# STM32F412CEU6 register map
File version: 1.0
Registers are 32-bit, access not given, reset 0x0 unless marked. A register's access mark holds for its fields unless they carry their own. Offsets are from the block's base; [hi:lo] are bit positions; {n}, {i} and the like mark numbered series; 'fields as' and 'values as' point back to an identical list.

## GPIOA
Base 0x40020000
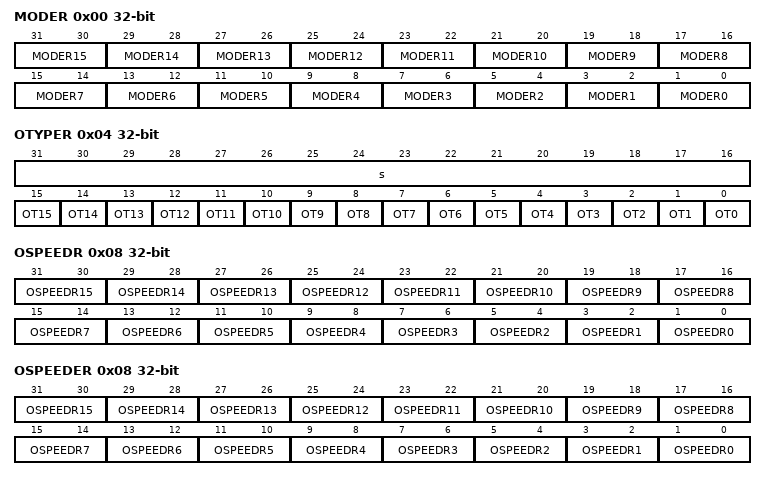
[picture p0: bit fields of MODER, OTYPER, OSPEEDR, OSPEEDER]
0x00 MODER
  [2n+1:2n] MODER{n} (n=0..15)
0x04 OTYPER
  [31:16] s, [n] OT{n} (n=0..15)
0x08 OSPEEDR
  [2n+1:2n] OSPEEDR{n} (n=0..15)
0x08 OSPEEDER
  [2n+1:2n] OSPEEDR{n} (n=0..15)
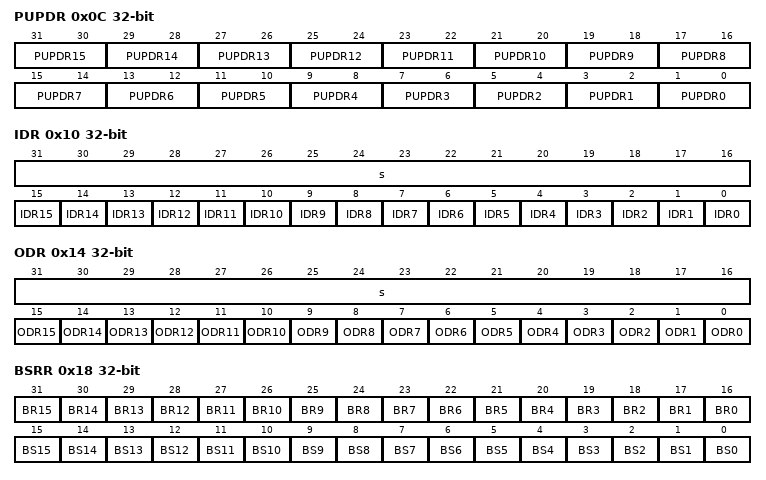
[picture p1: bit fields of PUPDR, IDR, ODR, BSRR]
0x0C PUPDR
  [2n+1:2n] PUPDR{n} (n=0..15)
0x10 IDR
  [31:16] s, [n] IDR{n} (n=0..15)
0x14 ODR
  [31:16] s, [n] ODR{n} (n=0..15)
0x18 BSRR
  [n+16] BR{n} (n=0..15), [n] BS{n} (n=0..15)
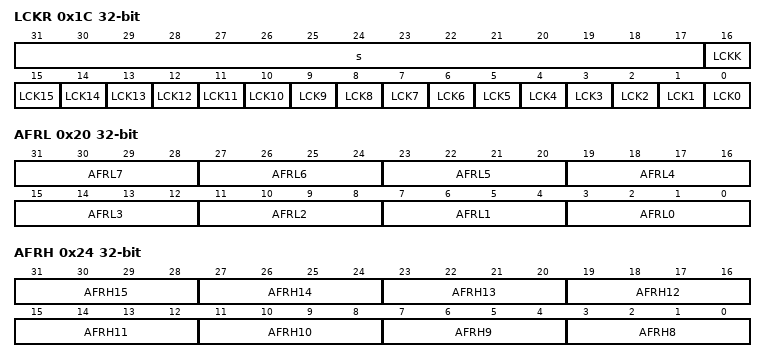
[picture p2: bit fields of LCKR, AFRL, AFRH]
0x1C LCKR
  [31:17] s, [16] LCKK, [n] LCK{n} (n=0..15)
0x20 AFRL
  [4n+3:4n] AFRL{n} (n=0..7)
0x24 AFRH
  [4n-29:4n-32] AFRH{n} (n=8..15)

## GPIOB
Base 0x40020400
Registers as GPIOA, without OSPEEDER.

## GPIOC
Base 0x40020800
Registers as GPIOA, without OSPEEDER.

## GPIOD
Base 0x40020C00
Registers as GPIOA, without OSPEEDER.

## GPIOE
Base 0x40021000
Registers as GPIOA, without OSPEEDER.

## GPIOF
Base 0x40021400
Registers as GPIOA, without OSPEEDER.

## GPIOG
Base 0x40021800
Registers as GPIOA, without OSPEEDER.

## GPIOH
Base 0x40021C00
Registers as GPIOA, without OSPEEDER.

## CRC
Base 0x40023000
0x00 DR
  [31:0] DATA
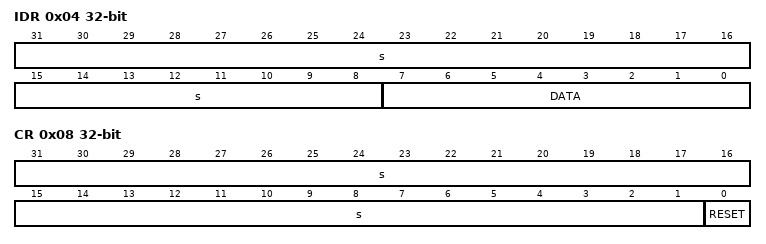
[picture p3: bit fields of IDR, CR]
0x04 IDR
  [31:8] s, [7:0] DATA
0x08 CR
  [31:1] s, [0] RESET

## FLASH
Base 0x40023C00
0x00 ACR
  [12] DCRST, [11] ICRST, [10] DCEN, [9] ICEN, [8] PRFTEN, [31:4] s, [3:0] LATENCY
0x04 KEYR
  [31:0] KEY
0x08 OPTKEYR
0x0C SR
  [16] BSY, [8] RDERR, [7] PGSERR, [6] PGPERR, [5] PGAERR, [4] WRPERR, [31:2] s, [1] OPERR, [0] EOP
0x10 CR
  [31] LOCK, [25] ERRIE, [24] EOPIE, [16] STRT, [9:8] PSIZE, [30:7] s, [6:3] SNB, [2] MER, [1] SER, [0] PG
0x14 OPTCR
  [31] SPRMOD, [27:16] nWRP, [15:8] RDP, [7] nRST_STDB, [6] nRST_STOP, [5] WDG_SW, [30:4] s, [3:2] BOR_LEV, [1] OPTSTRT, [0] OPTLOCK

## DMA1
Base 0x40026000
Same registers: DMA2 0x40026400
0x00 LISR
  [27] TCIF3, [26] HTIF3, [25] TEIF3, [24] DMEIF3, [22] FEIF3, [21] TCIF2, [20] HTIF2, [19] TEIF2, [18] DMEIF2, [16] FEIF2, [11] TCIF1, [10] HTIF1, [9] TEIF1, [8] DMEIF1, [6] FEIF1, [5] TCIF0, [4] HTIF0, [3] TEIF0, [2] DMEIF0, [31:1] s, [0] FEIF0
0x04 HISR
  [27] TCIF7, [26] HTIF7, [25] TEIF7, [24] DMEIF7, [22] FEIF7, [21] TCIF6, [20] HTIF6, [19] TEIF6, [18] DMEIF6, [16] FEIF6, [11] TCIF5, [10] HTIF5, [9] TEIF5, [8] DMEIF5, [6] FEIF5, [5] TCIF4, [4] HTIF4, [3] TEIF4, [2] DMEIF4, [31:1] s, [0] FEIF4
0x08 LIFCR
  [27] CTCIF3, [26] CHTIF3, [25] TEIF3, [24] CDMEIF3, [22] CFEIF3, [21] CTCIF2, [20] CHTIF2, [19] CTEIF2, [18] CDMEIF2, [16] CFEIF2, [11] CTCIF1, [10] CHTIF1, [9] CTEIF1, [8] CDMEIF1, [6] CFEIF1, [5] CTCIF0, [4] CHTIF0, [3] CTEIF0, [2] CDMEIF0, [31:1] s, [0] CFEIF0
0x08 S1CR
  [27:25] CHSEL, [24:23] MBURST, [22:21] PBURST, [31:20] s, [19] CT, [18] DBM, [17:16] PL, [15] PINCOS, [14:13] MSIZE, [12:11] PSIZE, [10] MINC, [9] PINC, [8] CIRC, [7:6] DIR, [5] PFCTRL, [4] TCIE, [3] HTIE, [2] TEIE, [1] DMEIE, [0] EN
0x0C HIFCR
  [27] CTCIF7, [26] CHTIF7, [25] CTEIF7, [24] CDMEIF7, [22] CFEIF7, [21] CTCIF6, [20] CHTIF6, [19] CTEIF6, [18] CDMEIF6, [16] CFEIF6, [11] CTCIF5, [10] CHTIF5, [9] CTEIF5, [8] CDMEIF5, [6] CFEIF5, [5] CTCIF4, [4] CHTIF4, [3] CTEIF4, [2] CDMEIF4, [31:1] s, [0] CFEIF4
0x10 S0CR
  fields as S1CR
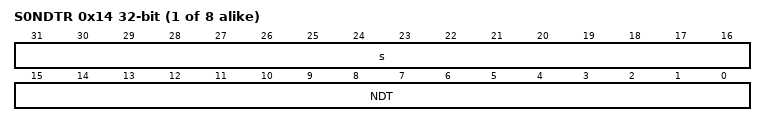
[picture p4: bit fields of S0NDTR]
{0x14+0x18*i} S{i}NDTR (i=0..7)
  [31:16] s, [15:0] NDT
{0x18+0x18*i} S{i}PAR (i=0..7)
  [31:0] PA
{0x1C+0x18*i} S{i}M0AR (i=0..7)
  [31:0] M0A
{0x20+0x18*i} S{i}M1AR (i=0..7)
  [31:0] M1A
{0x24+0x18*i} S{i}FCR (i=0..7)
  [7] FEIE, [31:6] s, [5:3] FS, [2] DMDIS, [1:0] FTH
{0x10+0x18*i} S{i}CR (i=2..7)
  fields as S1CR

## RNG
Base 0x50060800
0x00 CR
  [5] CED, [3] IE, [2] RNGEN, [31:0] s
0x04 SR
  [6] SEIS, [5] CEIS, [31:3] s, [2] SECS, [1] CECS, [0] DRDY
0x08 DR
  [31:0] RNDATA

## FSMC
Base 0x60000000
Same registers: FSMC 0xA0000000, FSMC 0xA0000000
0x00 BCR1
  [21] WFDIS, [20] CCLKEN, [19] CBURSTRW, [18:16] CPSIZE, [15] ASYNCWAIT, [14] EXTMOD, [13] WAITEN, [12] WREN, [11] WAITCFG, [9] WAITPOL, [8] BURSTEN, [31:7] s, [6] FACCEN, [5:4] MWID, [3:2] MTYP, [1] MUXEN, [0] MBKEN
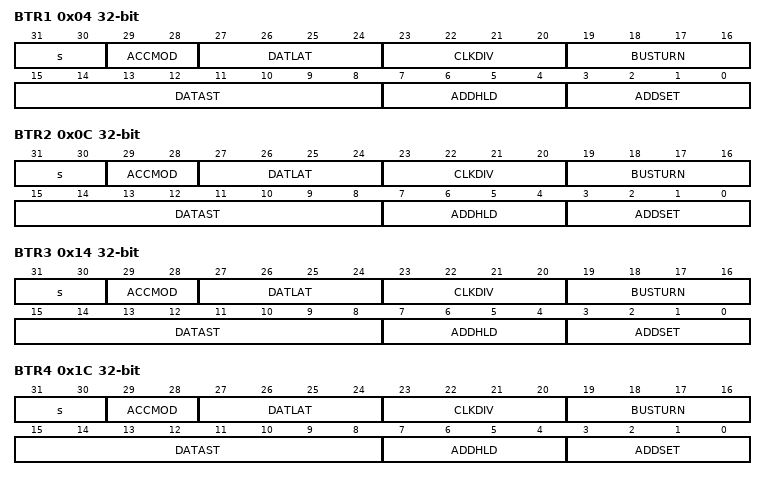
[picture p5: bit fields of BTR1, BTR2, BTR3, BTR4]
0x04 BTR1
  [31:30] s, [29:28] ACCMOD, [27:24] DATLAT, [23:20] CLKDIV, [19:16] BUSTURN, [15:8] DATAST, [7:4] ADDHLD, [3:0] ADDSET
0x08 BCR2
  [19] CBURSTRW, [18:16] CPSIZE, [15] ASYNCWAIT, [14] EXTMOD, [13] WAITEN, [12] WREN, [11] WAITCFG, [9] WAITPOL, [8] BURSTEN, [31:7] s, [6] FACCEN, [5:4] MWID, [3:2] MTYP, [1] MUXEN, [0] MBKEN
0x0C BTR2
  fields as BTR1
0x10 BCR3
  fields as BCR2
0x14 BTR3
  fields as BTR1
0x18 BCR4
  fields as BCR2
0x1C BTR4
  fields as BTR1
{0xFC+8i} BWTR{i} (i=1..4)
  [29:28] ACCMOD, [31:20] s, [19:16] BUSTURN, [15:8] DATAST, [7:4] ADDHLD, [3:0] ADDSET

## QUADSPI
Base 0x90000000
0x00 CR
  [31:24] PRESCALER, [23] PMM, [22] APMS, [20] TOIE, [19] SMIE, [18] FTIE, [17] TCIE, [16] TEIE, [12:8] FTHRES, [7] FSEL, [6] DFM, [21:5] s, [4] SSHIFT, [3] TCEN, [2] DMAEN, [1] ABORT, [0] EN
0x04 DCR
  [20:16] FSIZE, [10:8] CSHT, [31:1] s, [0] CKMODE
0x08 SR
  [13:8] FLEVEL, [31:6] s, [5] BUS, [4] TOF, [3] SMF, [2] FTF, [1] TCF, [0] TEF
0x0C FCR
  [4] CTOF, [3] CSMF, [31:2] s, [1] CTCF, [0] CTEF
0x10 DLR
  [31:0] DL
0x14 CCR
  [31] DDRM, [30] DHHC, [28] SIOO, [27:26] FMODE, [25:24] DMODE, [29:23] s, [22:18] DCYC, [17:16] ABSIZE, [15:14] ABMODE, [13:12] ADSIZE, [11:10] ADMODE, [9:8] IMODE, [7:0] INSTRUCTION
0x18 AR
  [31:0] ADDRESS
0x1C ABR
  [31:0] ALTERNATE
0x20 DR
  [31:0] DATA
0x24 PSMKR
  [31:0] MASK
0x28 PSMAR
  [31:0] MATCH
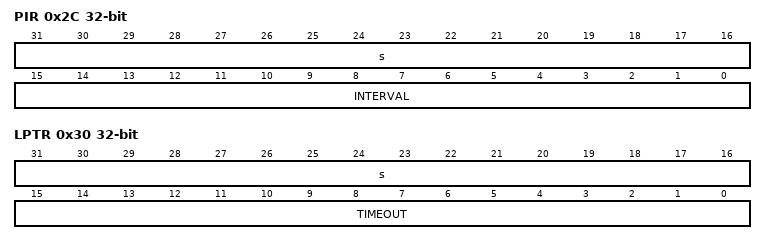
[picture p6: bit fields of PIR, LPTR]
0x2C PIR
  [31:16] s, [15:0] INTERVAL
0x30 LPTR
  [31:16] s, [15:0] TIMEOUT
